# MSP430FR5969 register map
Vendor: msp430gen; File version: v0.4.0
Registers are 16-bit, read-write, reset 0x0 unless marked. A register's access mark holds for its fields unless they carry their own. Offsets are from the block's base; lines under a group give offsets from that group; [hi:lo] are bit positions; {n}, {i} and the like mark numbered series; 'fields as' and 'values as' point back to an identical list; <NAME> marks a mode.

## Memory map
0x00000100 SFR — SFR Special Function Registers
0x00000120 PMM — PMM Power Management System
0x00000140 FRAM
0x00000150 CRC16
0x0000015C WATCHDOG_TIMER
0x00000160 CS — CS Clock System
0x00000180 SYS — SYS System Module
0x000001B0 SHARED_REFERENCE
0x00000200 PORT_1_2
0x00000220 PORT_3_4
0x00000320 PORT_J
0x00000340 TIMER_0_A3
0x00000380 TIMER_1_A3
0x000003C0 TIMER_0_B7
0x00000400 TIMER_2_A2
0x0000043E CAPACITIVE_TOUCH_IO_0
0x00000440 TIMER_3_A2
0x0000047E CAPACITIVE_TOUCH_IO_1
0x000004A0 RTC_B_REAL_TIME_CLOCK
0x000004C0 MPY_16 — MPY 16 Multiplier 16 Bit Mode
0x000004D0 MPY_32 — MPY 32 Multiplier 32 Bit Mode
0x00000500 DMA
0x000005A0 MPU
0x000005C0 USCI_A0_UART_MODE
0x000005C0 USCI_A0_SPI_MODE
0x000005E0 USCI_A1_UART_MODE
0x000005E0 USCI_A1_SPI_MODE
0x00000640 USCI_B0_I2C_MODE
0x00000640 USCI_B0_SPI_MODE
0x00000800 ADC12
0x000008C0 COMPARATOR_E
0x000009C0 AES_ACCELERATOR
0x0000FF80 _INTERRUPTS

## Interrupts
30 AES256 (_INTERRUPTS) — 0xFFCC AES256
31 RTC (_INTERRUPTS) — 0xFFCE RTC
32 PORT4 (_INTERRUPTS) — 0xFFD0 Port 4
33 PORT3 (_INTERRUPTS) — 0xFFD2 Port 3
34 TIMER3_A1 (_INTERRUPTS) — 0xFFD4 Timer3_A2 CC1, TA
35 TIMER3_A0 (_INTERRUPTS) — 0xFFD6 Timer3_A2 CC0
36 PORT2 (_INTERRUPTS) — 0xFFD8 Port 2
37 TIMER2_A1 (_INTERRUPTS) — 0xFFDA Timer2_A2 CC1, TA
38 TIMER2_A0 (_INTERRUPTS) — 0xFFDC Timer2_A2 CC0
39 PORT1 (_INTERRUPTS) — 0xFFDE Port 1
40 TIMER1_A1 (_INTERRUPTS) — 0xFFE0 Timer1_A3 CC1-2, TA
41 TIMER1_A0 (_INTERRUPTS) — 0xFFE2 Timer1_A3 CC0
42 DMA (_INTERRUPTS) — 0xFFE4 DMA
43 USCI_A1 (_INTERRUPTS) — 0xFFE6 USCI A1 Receive/Transmit
44 TIMER0_A1 (_INTERRUPTS) — 0xFFE8 Timer0_A3 CC1-2, TA
45 TIMER0_A0 (_INTERRUPTS) — 0xFFEA Timer0_A3 CC0
46 ADC12 (_INTERRUPTS) — 0xFFEC ADC
47 USCI_B0 (_INTERRUPTS) — 0xFFEE USCI B0 Receive/Transmit
48 USCI_A0 (_INTERRUPTS) — 0xFFF0 USCI A0 Receive/Transmit
49 WDT (_INTERRUPTS) — 0xFFF2 Watchdog Timer
50 TIMER0_B1 (_INTERRUPTS) — 0xFFF4 Timer0_B7 CC1-6, TB
51 TIMER0_B0 (_INTERRUPTS) — 0xFFF6 Timer0_B7 CC0
52 COMP_E (_INTERRUPTS) — 0xFFF8 Comparator E
53 UNMI (_INTERRUPTS) — 0xFFFA User Non-maskable
54 SYSNMI (_INTERRUPTS) — 0xFFFC System Non-maskable

## PORT_1_2
Base 0x00000200
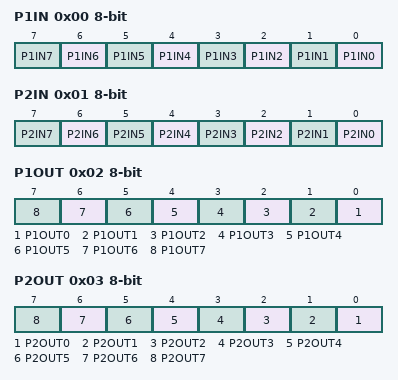
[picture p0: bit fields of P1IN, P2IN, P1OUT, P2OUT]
0x00 P1IN 8-bit — Port 1 Input
  [n] P1IN{n} (n=0..7)
0x01 P2IN 8-bit — Port 2 Input
  [n] P2IN{n} (n=0..7)
0x02 P1OUT 8-bit — Port 1 Output
  [n] P1OUT{n} (n=0..7)
0x03 P2OUT 8-bit — Port 2 Output
  [n] P2OUT{n} (n=0..7)
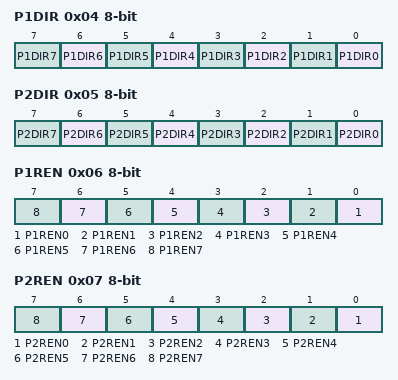
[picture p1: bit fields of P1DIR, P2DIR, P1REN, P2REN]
0x04 P1DIR 8-bit — Port 1 Direction
  [n] P1DIR{n} (n=0..7)
0x05 P2DIR 8-bit — Port 2 Direction
  [n] P2DIR{n} (n=0..7)
0x06 P1REN 8-bit — Port 1 Resistor Enable
  [n] P1REN{n} (n=0..7)
0x07 P2REN 8-bit — Port 2 Resistor Enable
  [n] P2REN{n} (n=0..7)
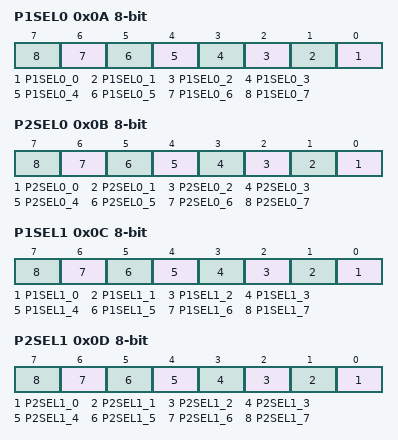
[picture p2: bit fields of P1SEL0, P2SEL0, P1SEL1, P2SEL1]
0x0A P1SEL0 8-bit — Port 1 Selection 0
  [n] P1SEL0_{n} (n=0..7)
0x0B P2SEL0 8-bit — Port 2 Selection 0
  [n] P2SEL0_{n} (n=0..7)
0x0C P1SEL1 8-bit — Port 1 Selection 1
  [n] P1SEL1_{n} (n=0..7)
0x0D P2SEL1 8-bit — Port 2 Selection 1
  [n] P2SEL1_{n} (n=0..7)
0x0E P1IV — Port 1 Interrupt Vector Word
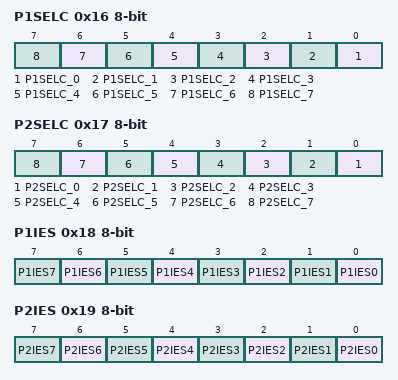
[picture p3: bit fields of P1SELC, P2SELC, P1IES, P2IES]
0x16 P1SELC 8-bit — Port 1 Complement Selection
  [n] P1SELC_{n} (n=0..7)
0x17 P2SELC 8-bit — Port 2 Complement Selection
  [n] P2SELC_{n} (n=0..7)
0x18 P1IES 8-bit — Port 1 Interrupt Edge Select
  [n] P1IES{n} (n=0..7)
0x19 P2IES 8-bit — Port 2 Interrupt Edge Select
  [n] P2IES{n} (n=0..7)
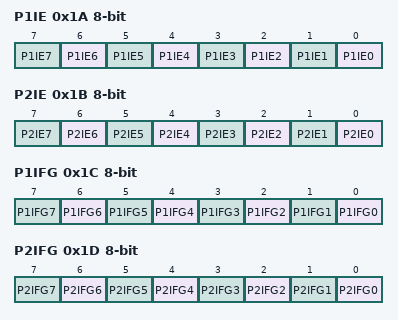
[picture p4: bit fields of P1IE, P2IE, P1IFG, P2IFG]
0x1A P1IE 8-bit — Port 1 Interrupt Enable
  [n] P1IE{n} (n=0..7)
0x1B P2IE 8-bit — Port 2 Interrupt Enable
  [n] P2IE{n} (n=0..7)
0x1C P1IFG 8-bit — Port 1 Interrupt Flag
  [n] P1IFG{n} (n=0..7)
0x1D P2IFG 8-bit — Port 2 Interrupt Flag
  [n] P2IFG{n} (n=0..7)
0x1E P2IV — Port 2 Interrupt Vector Word

## PORT_3_4
Base 0x00000220
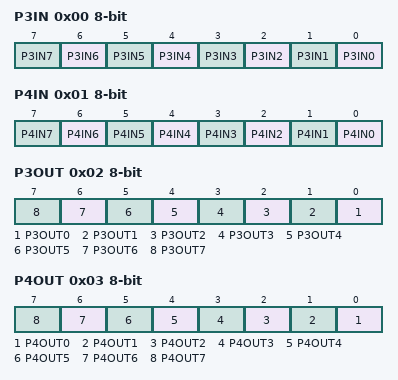
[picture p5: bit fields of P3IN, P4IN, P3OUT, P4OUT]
0x00 P3IN 8-bit — Port 3 Input
  [n] P3IN{n} (n=0..7)
0x01 P4IN 8-bit — Port 4 Input
  [n] P4IN{n} (n=0..7)
0x02 P3OUT 8-bit — Port 3 Output
  [n] P3OUT{n} (n=0..7)
0x03 P4OUT 8-bit — Port 4 Output
  [n] P4OUT{n} (n=0..7)
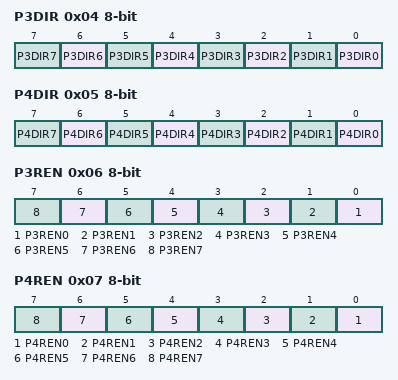
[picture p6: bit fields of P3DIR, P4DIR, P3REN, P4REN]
0x04 P3DIR 8-bit — Port 3 Direction
  [n] P3DIR{n} (n=0..7)
0x05 P4DIR 8-bit — Port 4 Direction
  [n] P4DIR{n} (n=0..7)
0x06 P3REN 8-bit — Port 3 Resistor Enable
  [n] P3REN{n} (n=0..7)
0x07 P4REN 8-bit — Port 4 Resistor Enable
  [n] P4REN{n} (n=0..7)
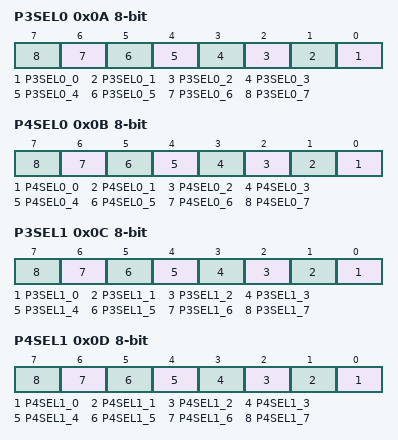
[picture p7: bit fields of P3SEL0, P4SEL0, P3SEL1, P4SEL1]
0x0A P3SEL0 8-bit — Port 3 Selection 0
  [n] P3SEL0_{n} (n=0..7)
0x0B P4SEL0 8-bit — Port 4 Selection 0
  [n] P4SEL0_{n} (n=0..7)
0x0C P3SEL1 8-bit — Port 3 Selection 1
  [n] P3SEL1_{n} (n=0..7)
0x0D P4SEL1 8-bit — Port 4 Selection 1
  [n] P4SEL1_{n} (n=0..7)
0x0E P3IV — Port 3 Interrupt Vector Word
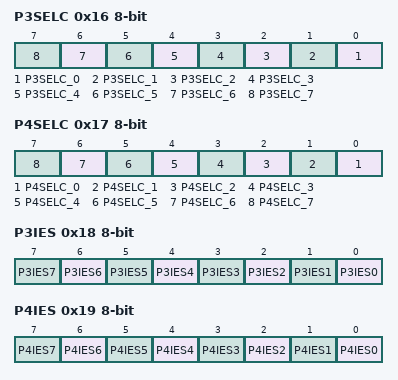
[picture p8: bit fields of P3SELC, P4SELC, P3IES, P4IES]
0x16 P3SELC 8-bit — Port 3 Complement Selection
  [n] P3SELC_{n} (n=0..7)
0x17 P4SELC 8-bit — Port 4 Complement Selection
  [n] P4SELC_{n} (n=0..7)
0x18 P3IES 8-bit — Port 3 Interrupt Edge Select
  [n] P3IES{n} (n=0..7)
0x19 P4IES 8-bit — Port 4 Interrupt Edge Select
  [n] P4IES{n} (n=0..7)
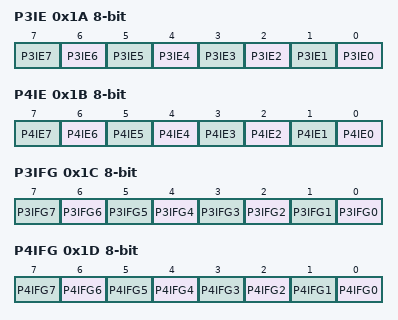
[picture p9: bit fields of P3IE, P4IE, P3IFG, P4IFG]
0x1A P3IE 8-bit — Port 3 Interrupt Enable
  [n] P3IE{n} (n=0..7)
0x1B P4IE 8-bit — Port 4 Interrupt Enable
  [n] P4IE{n} (n=0..7)
0x1C P3IFG 8-bit — Port 3 Interrupt Flag
  [n] P3IFG{n} (n=0..7)
0x1D P4IFG 8-bit — Port 4 Interrupt Flag
  [n] P4IFG{n} (n=0..7)
0x1E P4IV — Port 4 Interrupt Vector Word
